VERSION "1.0"

NS_ :

BS_:

BU_: PCM1 FOO

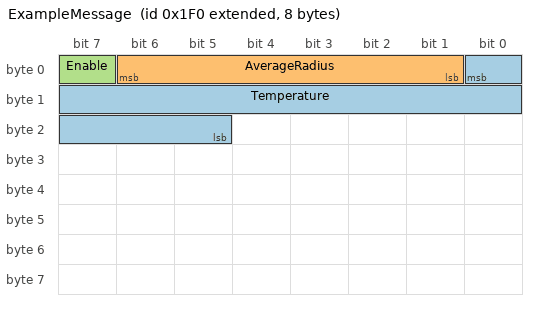
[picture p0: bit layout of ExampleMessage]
BO_ 2147484144 ExampleMessage: 8 PCM1
 SG_ Temperature : 0|12@0- (0.01,250) [229.52|270.47] "degK"  PCM1,FOO
 SG_ AverageRadius : 6|6@0+ (0.1,0) [0|5] "m" Vector__XXX
 SG_ Enable : 7|1@0+ (1,0) [0|0] "-" Vector__XXX

CM_ BO_ 2147484144 "Example message used as template in MotoHawk models.";
BA_DEF_  "BusType" STRING ;
BA_DEF_ BO_  "VFrameFormat" ENUM  "StandardCAN","ExtendedCAN","reserved","J1939PG","reserved","reserved","reserved","reserved","reserved","reserved","reserved","reserved","reserved","reserved","StandardCAN_FD","ExtendedCAN_FD";
BA_DEF_ BO_  "CANFD_BRS" ENUM  "0","1";
BA_DEF_DEF_  "BusType" "";
BA_DEF_DEF_  "VFrameFormat" "StandardCAN";
BA_DEF_DEF_  "CANFD_BRS" "1";
BA_ "BusType" "CAN FD";
BA_ "VFrameFormat" BO_ 2147484144 15;
VAL_ 2147484144 Enable 0 "Disabled" 1 "Enabled" ;
